# STM32L552xx register map
File version: 1.0
Registers are 32-bit, read-write, reset 0x0 unless marked. A register's access mark holds for its fields unless they carry their own. Offsets are from the block's base; [hi:lo] are bit positions; {n}, {i} and the like mark numbered series; 'fields as' and 'values as' point back to an identical list.

## IWDG — Independent WATCHDOG
Base 0x40003000
Same registers: IWDG_S 0x50003000
0x00 KR — IWDG Key register
  [15:0] KEY — Key value (write only, read 0000h)
0x04 PR — IWDG Prescaler register
  [2:0] PR — PR[2:0] (Prescaler divider)
0x08 RLR — IWDG Reload register
  [11:0] RL — Watchdog counter reload value
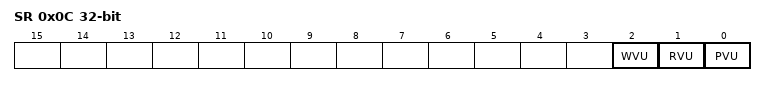
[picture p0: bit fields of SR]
0x0C SR — IWDG Status register
  [2] WVU — Watchdog counter window value update
  [1] RVU — Watchdog counter reload value update
  [0] PVU — Watchdog prescaler value update
0x10 WINR — IWDG Window register
  [11:0] WIN — Watchdog counter window value

## TAMP — Tamper and backup registers
Base 0x40003400
Same registers: TAMP_S 0x50003400
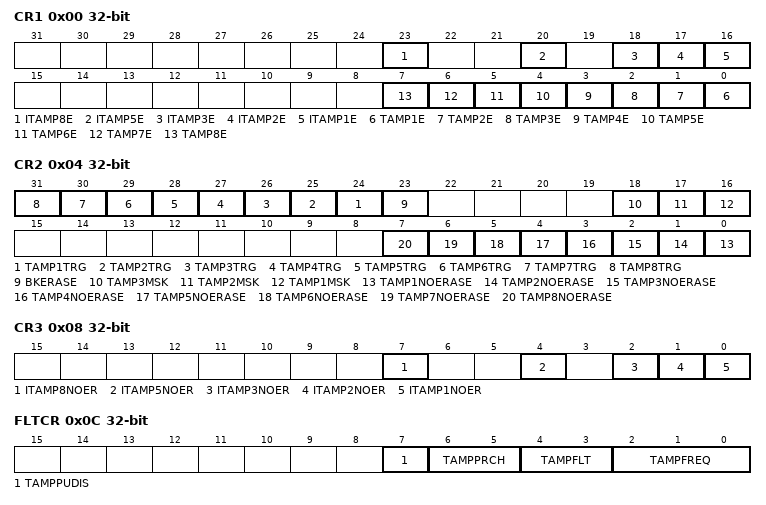
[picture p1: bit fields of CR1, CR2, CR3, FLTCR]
0x00 CR1 — TAMP configuration register 1
  [23] ITAMP8E, [20] ITAMP5E, [18] ITAMP3E, [17] ITAMP2E, [16] ITAMP1E, [n-1] TAMP{n}E (n=1..8)
0x04 CR2 — TAMP configuration register 2
  [n+23] TAMP{n}TRG (n=1..8), [23] BKERASE, [18] TAMP3MSK, [17] TAMP2MSK, [16] TAMP1MSK, [n-1] TAMP{n}NOERASE (n=1..8)
0x08 CR3 — TAMP configuration register 3
  [7] ITAMP8NOER, [4] ITAMP5NOER, [2] ITAMP3NOER, [1] ITAMP2NOER, [0] ITAMP1NOER
0x0C FLTCR — TAMP filter control register
  [7] TAMPPUDIS
  [6:5] TAMPPRCH
    0=DURATION_1RTCCLK (Tamper pins are pre-charged before sampling during 1 RTCCLK cycle); 1=DURATION_2RTCCLK (Tamper pins are pre-charged before sampling during 2 RTCCLK cycles); 2=DURATION_4RTCCLK (Tamper pins are pre-charged before sampling during 4 RTCCLK cycles); 3=DURATION_8RTCCLK (Tamper pins are pre-charged before sampling during 8 RTCCLK cycles)
  [4:3] TAMPFLT
    0=DISABLE (Tamper filter is disabled); 1=FILTER_2SAMPLE (Tamper is activated after 2 consecutive samples at the active level); 2=FILTER_4SAMPLE (Tamper is activated after 4 consecutive samples at the active level); 3=FILTER_8SAMPLE (Tamper is activated after 8 consecutive samples at the active level.)
  [2:0] TAMPFREQ
    0=SAMPLFREQDIV_32768 (Each of the tamper inputs are sampled with a frequency = RTCCLK / 32768); 1=SAMPLFREQDIV_16384 (Each of the tamper inputs are sampled with a frequency = RTCCLK / 16384); 2=SAMPLFREQDIV_8192 (Each of the tamper inputs are sampled with a frequency = RTCCLK / 8192); 3=SAMPLFREQDIV_4096 (Each of the tamper inputs are sampled with a frequency = RTCCLK / 4096); 4=SAMPLFREQDIV_2048 (Each of the tamper inputs are sampled with a frequency = RTCCLK / 2048); 5=SAMPLFREQDIV_1024 (Each of the tamper inputs are sampled with a frequency = RTCCLK / 1024); 6=SAMPLFREQDIV_512 (Each of the tamper inputs are sampled with a frequency = RTCCLK / 512); 7=SAMPLFREQDIV_256 (Each of the tamper inputs are sampled with a frequency = RTCCLK / 256)
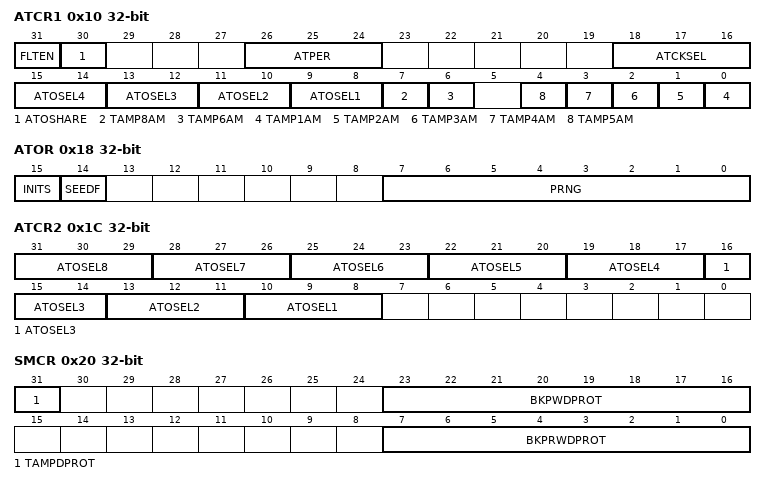
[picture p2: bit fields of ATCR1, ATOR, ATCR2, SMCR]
0x10 ATCR1 — TAMP active tamper control register 1
  [31] FLTEN, [30] ATOSHARE, [26:24] ATPER, [18:16] ATCKSEL, [2n+7:2n+6] ATOSEL{n} (n=1..4), [7] TAMP8AM, [6] TAMP6AM, [n-1] TAMP{n}AM (n=1..5)
0x14 ATSEEDR — TAMP active tamper seed register
  [31:0] SEED
0x18 ATOR — TAMP active tamper output register
  [15] INITS, [14] SEEDF, [7:0] PRNG
0x1C ATCR2 — TAMP active tamper control register 2
  [3n+7:3n+5] ATOSEL{n} (n=1..8)
0x20 SMCR — TAMP secure mode control register
  [31] TAMPDPROT
    0=YES (TAMP full secure); 1=NO (TAMP is not secure)
  [23:16] BKPWDPROT
  [7:0] BKPRWDPROT
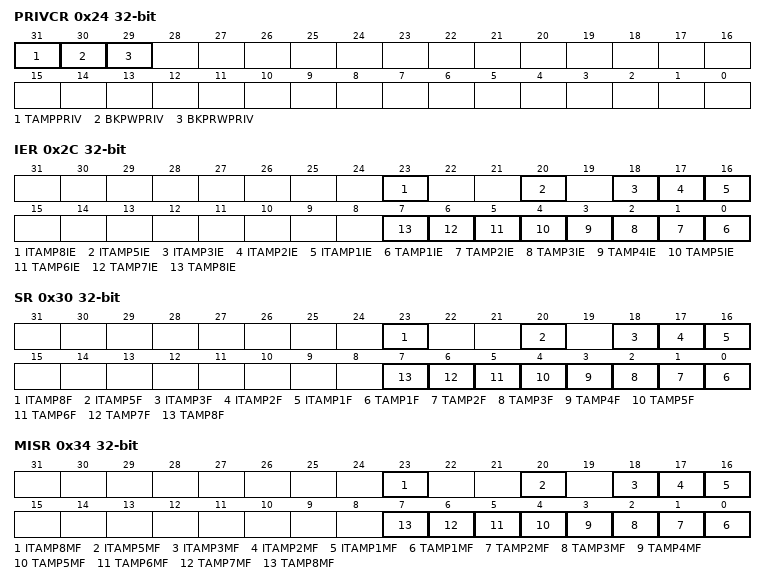
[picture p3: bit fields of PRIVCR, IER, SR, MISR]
0x24 PRIVCR — TAMP privilege mode control register
  [31] TAMPPRIV
    1=YES (TAMP full privilege); 0=NO (TAMP is not privilege)
  [30] BKPWPRIV
  [29] BKPRWPRIV
0x2C IER — TAMP interrupt enable register
  [23] ITAMP8IE, [20] ITAMP5IE, [18] ITAMP3IE, [17] ITAMP2IE, [16] ITAMP1IE, [n-1] TAMP{n}IE (n=1..8)
0x30 SR — TAMP status register
  [23] ITAMP8F, [20] ITAMP5F, [18] ITAMP3F, [17] ITAMP2F, [16] ITAMP1F, [n-1] TAMP{n}F (n=1..8)
0x34 MISR — TAMP masked interrupt status register
  [23] ITAMP8MF, [20] ITAMP5MF, [18] ITAMP3MF, [17] ITAMP2MF, [16] ITAMP1MF, [n-1] TAMP{n}MF (n=1..8)
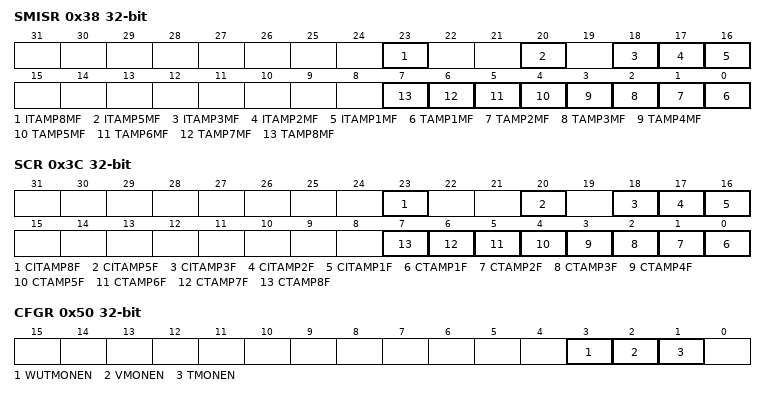
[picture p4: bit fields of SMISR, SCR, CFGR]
0x38 SMISR — TAMP secure masked interrupt status register
  fields as MISR
0x3C SCR — TAMP status clear register
  [23] CITAMP8F, [20] CITAMP5F, [18] CITAMP3F, [17] CITAMP2F, [16] CITAMP1F, [n-1] CTAMP{n}F (n=1..8)
0x40 COUNTR — TAMP monotonic counter register
  [31:16] COUNTR
0x50 CFGR — TAMP configuration register
  [3] WUTMONEN, [2] VMONEN, [1] TMONEN
{0x100+4i} BKP{i}R (i=0..31) — TAMP backup register {i}
